VERSION ""

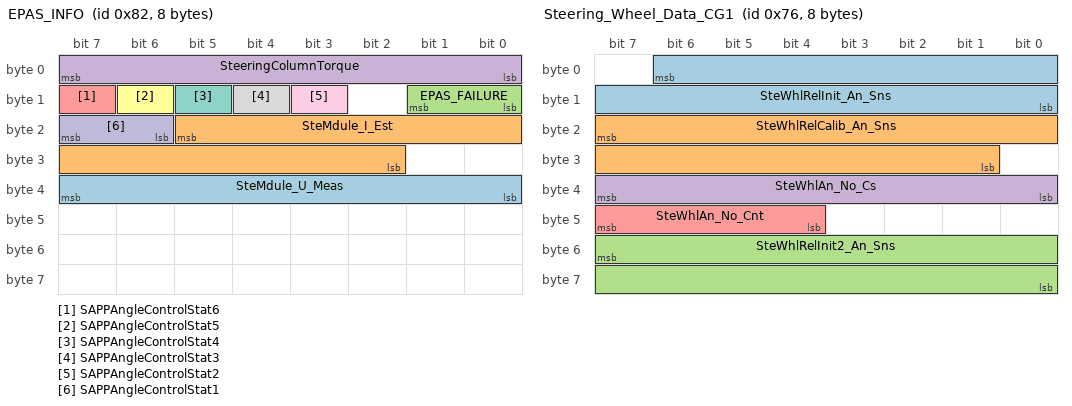
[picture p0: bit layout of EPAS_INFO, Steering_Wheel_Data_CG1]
BO_ 130 EPAS_INFO: 8 XXX
 SG_ SteMdule_U_Meas : 39|8@0+ (0.05,6.0) [0|0] "Volts" XXX
 SG_ SteMdule_I_Est : 21|12@0+ (0.05,-64.0) [0|0] "Amps" XXX
 SG_ EPAS_FAILURE : 9|2@0+ (1,0) [0|0] "" XXX
 SG_ SteeringColumnTorque : 7|8@0+ (0.0625,-8.0) [0|0] "Nm" XXX
 SG_ SAPPAngleControlStat6 : 15|1@0+ (1,0) [0|0] "" XXX
 SG_ SAPPAngleControlStat5 : 14|1@0+ (1,0) [0|0] "" XXX
 SG_ SAPPAngleControlStat4 : 13|1@0+ (1,0) [0|0] "" XXX
 SG_ SAPPAngleControlStat3 : 12|1@0+ (1,0) [0|0] "" XXX
 SG_ SAPPAngleControlStat2 : 11|1@0+ (1,0) [0|0] "" XXX
 SG_ SAPPAngleControlStat1 : 23|2@0+ (1,0) [0|0] "" XXX

BO_ 118 Steering_Wheel_Data_CG1: 8 XXX
 SG_ SteWhlRelInit_An_Sns : 6|15@0+ (0.1,-1600.0) [0|0] "deg" XXX
 SG_ SteWhlRelCalib_An_Sns : 23|15@0+ (0.1,-1600.0) [0|0] "deg" XXX
 SG_ SteWhlRelInit2_An_Sns : 55|16@0+ (0.1,-3200.0) [0|0] "deg" XXX
 SG_ SteWhlAn_No_Cs : 39|8@0+ (1,0) [0|0] "" XXX
 SG_ SteWhlAn_No_Cnt : 47|4@0+ (1,0) [0|0] "Counts" XXX

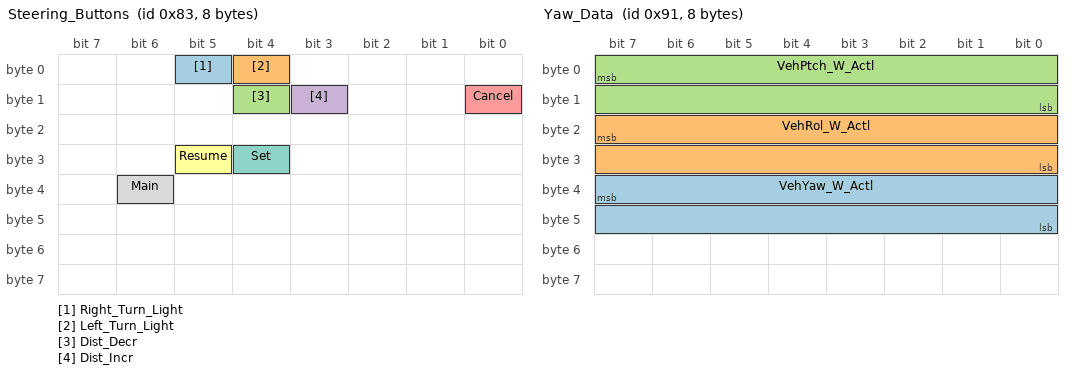
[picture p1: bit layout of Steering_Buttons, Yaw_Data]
BO_ 131 Steering_Buttons: 8 XXX
 SG_ Right_Turn_Light : 5|1@0+ (1,0) [0|0] "" XXX
 SG_ Left_Turn_Light : 4|1@0+ (1,0) [0|0] "" XXX
 SG_ Dist_Decr : 12|1@0+ (1,0) [0|0] "" XXX
 SG_ Dist_Incr : 11|1@0+ (1,0) [0|0] "" XXX
 SG_ Cancel : 8|1@0+ (1,0) [0|0] "" XXX
 SG_ Resume : 29|1@0+ (1,0) [0|0] "" XXX
 SG_ Set : 28|1@0+ (1,0) [0|0] "" XXX
 SG_ Main : 38|1@0+ (1,0) [0|0] "" XXX

BO_ 145 Yaw_Data: 8 XXX
 SG_ VehYaw_W_Actl : 39|16@0+ (0.0002,-6.5) [0|0] "rad/s" XXX
 SG_ VehRol_W_Actl : 23|16@0+ (0.0002,-6.5) [0|0] "rad/s" XXX
 SG_ VehPtch_W_Actl : 7|16@0+ (0.0002,-6.5) [0|0] "rad/s" XXX

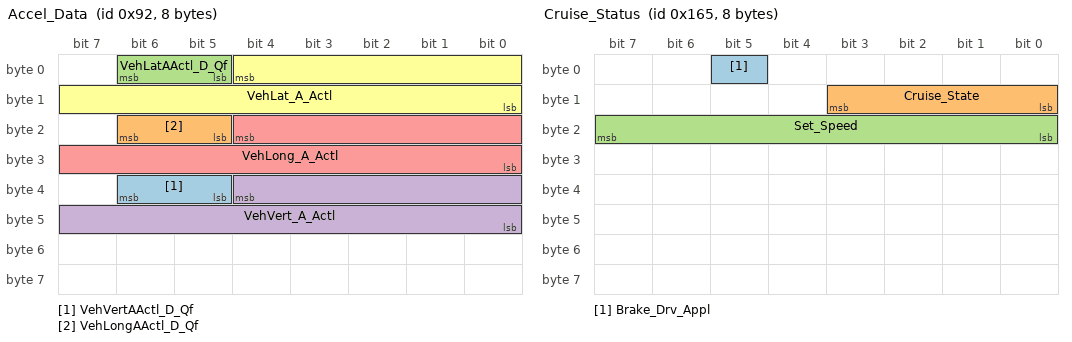
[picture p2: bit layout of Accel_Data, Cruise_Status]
BO_ 146 Accel_Data: 8 XXX
 SG_ VehVertAActl_D_Qf : 38|2@0+ (1,0) [0|0] "" XXX
 SG_ VehLongAActl_D_Qf : 22|2@0+ (1,0) [0|0] "" XXX
 SG_ VehLatAActl_D_Qf : 6|2@0+ (1,0) [0|0] "" XXX
 SG_ VehVert_A_Actl : 36|13@0+ (0.01,-40.0) [0|0] "m/s^2" XXX
 SG_ VehLong_A_Actl : 20|13@0+ (0.01,-40.0) [0|0] "m/s^2" XXX
 SG_ VehLat_A_Actl : 4|13@0+ (0.01,-40.0) [0|0] "m/s^2" XXX

BO_ 357 Cruise_Status: 8 XXX
 SG_ Brake_Drv_Appl : 5|1@0+ (1,0) [0|0] "" XXX
 SG_ Cruise_State : 11|4@0+ (1,0) [0|0] "" XXX
 SG_ Set_Speed : 23|8@0+ (1,0) [0|0] "" XXX

BO_ 516 EngineData_14: 8 XXX
 SG_ ApedPosScal_Pc_Actl : 1|10@0+ (0.1,0) [0|0] "%" XXX

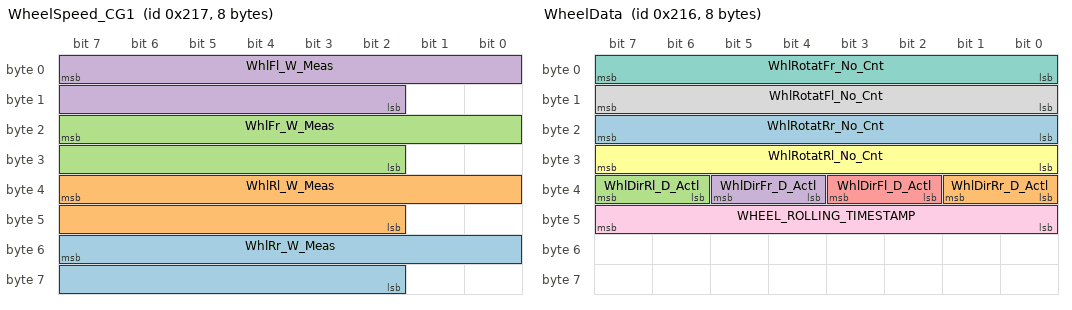
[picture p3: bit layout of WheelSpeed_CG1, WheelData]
BO_ 535 WheelSpeed_CG1: 8 XXX
 SG_ WhlRr_W_Meas : 55|14@0+ (0.04,0) [0|0] "rad/s" XXX
 SG_ WhlRl_W_Meas : 39|14@0+ (0.04,0) [0|0] "rad/s" XXX
 SG_ WhlFr_W_Meas : 23|14@0+ (0.04,0) [0|0] "rad/s" XXX
 SG_ WhlFl_W_Meas : 7|14@0+ (0.04,0) [0|0] "rad/s" XXX

BO_ 534 WheelData: 8 XXX
 SG_ WhlRotatRr_No_Cnt : 23|8@0+ (1,0) [0|0] "" XXX
 SG_ WhlDirRr_D_Actl : 33|2@0+ (1,0) [0|0] "" XXX
 SG_ WhlDirRl_D_Actl : 39|2@0+ (1,0) [0|0] "" XXX
 SG_ WhlDirFr_D_Actl : 37|2@0+ (1,0) [0|0] "" XXX
 SG_ WhlDirFl_D_Actl : 35|2@0+ (1,0) [0|0] "" XXX
 SG_ WhlRotatRl_No_Cnt : 31|8@0+ (1,0) [0|0] "" XXX
 SG_ WhlRotatFr_No_Cnt : 7|8@0+ (1,0) [0|0] "" XXX
 SG_ WhlRotatFl_No_Cnt : 15|8@0+ (1,0) [0|0] "" XXX
 SG_ WHEEL_ROLLING_TIMESTAMP : 47|8@0+ (1,0) [0|0] "" XXX

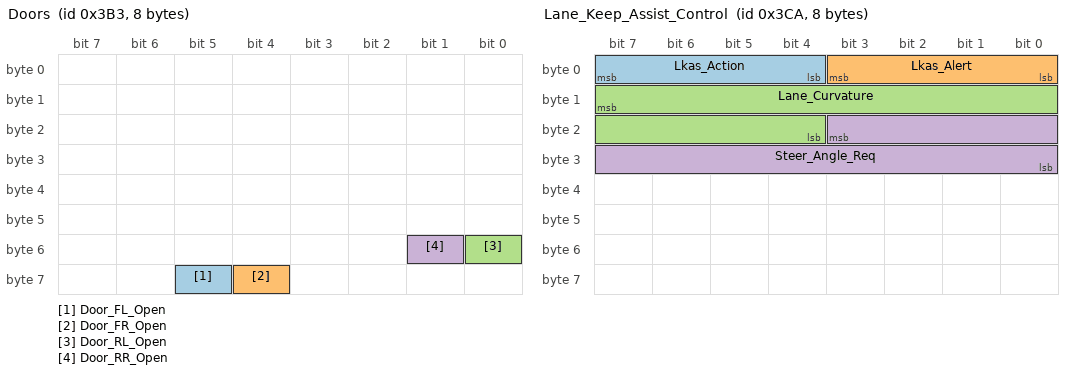
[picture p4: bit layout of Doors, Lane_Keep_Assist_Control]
BO_ 947 Doors: 8 XXX
 SG_ Door_FL_Open : 61|1@0+ (1,0) [0|0] "" XXX
 SG_ Door_FR_Open : 60|1@0+ (1,0) [0|0] "" XXX
 SG_ Door_RL_Open : 48|1@0+ (1,0) [0|0] "" XXX
 SG_ Door_RR_Open : 49|1@0+ (1,0) [0|0] "" XXX

BO_ 963 BCM_to_HS_Body: 8 XXX
 SG_ Brake_Lights : 8|1@0+ (1,0) [0|0] "" XXX

BO_ 970 Lane_Keep_Assist_Control: 8 XXX
 SG_ Lkas_Action : 7|4@0+ (1,0) [0|15] "" XXX
 SG_ Lkas_Alert : 3|4@0+ (1,0) [0|15] "" XXX
 SG_ Lane_Curvature : 15|12@0+ (5e-06,-0.01) [0|0] "1/m" XXX
 SG_ Steer_Angle_Req : 19|12@0+ (0.04297,-88.00445) [0|0] "deg" XXX

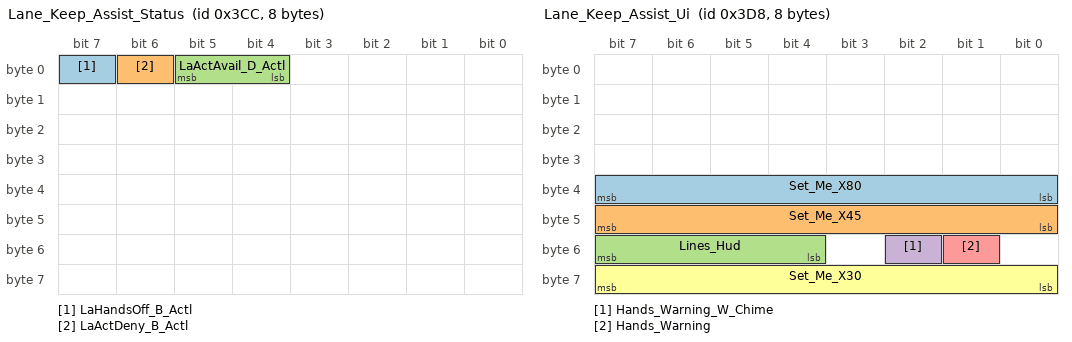
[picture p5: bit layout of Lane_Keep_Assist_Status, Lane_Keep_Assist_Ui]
BO_ 972 Lane_Keep_Assist_Status: 8 XXX
 SG_ LaHandsOff_B_Actl : 7|1@0+ (1,0) [0|0] "" XXX
 SG_ LaActDeny_B_Actl : 6|1@0+ (1,0) [0|0] "" XXX
 SG_ LaActAvail_D_Actl : 5|2@0+ (1,0) [0|0] "" XXX

BO_ 984 Lane_Keep_Assist_Ui: 8 XXX
 SG_ Set_Me_X80 : 39|8@0+ (1,0) [0|255] "" XXX
 SG_ Set_Me_X45 : 47|8@0+ (1,0) [0|255] "" XXX
 SG_ Lines_Hud : 55|4@0+ (1,0) [0|15] "" XXX
 SG_ Hands_Warning_W_Chime : 50|1@0+ (1,0) [0|1] "" XXX
 SG_ Hands_Warning : 49|1@0+ (1,0) [0|1] "" XXX
 SG_ Set_Me_X30 : 63|8@0+ (1,0) [0|255] "" XXX

BU_: ADAS RADAR NEO XXX

CM_ SG_ 970 Lkas_Action "only vals 4, 5, 8, 9 seem to work. 4 and 5 are a bit smoother" ;

VAL_ 513 STATE 5 "FAULT_TIMEOUT" 4 "FAULT_STARTUP" 3 "FAULT_SCE" 2 "FAULT_SEND" 1 "FAULT_BAD_CHECKSUM" 0 "NO_FAULT" ;

VAL_ 780 CRUISE_SPEED 255 "no_speed" 252 "stopped";
VAL_ 780 HUD_LEAD 3 "acc_off" 2 "solid_car" 1 "dashed_car" 0 "no_car";
VAL_ 884 DASHBOARD_ALERT 0 "none" 51 "acc_problem" 55 "cmbs_problem" 75 "key_not_detected" 79 "fasten_seatbelt" 111 "lkas_problem" 131 "brake_system_problem" 132 "brake_hold_problem" 139 "tbd" 161 "door_open";
VAL_ 891 WIPERS 4 "High" 2 "Low" 0 "Off";

VAL_ 506 FCW 3 "fcw" 2 "fcw" 1 "fcw" 0 "no_fcw";
VAL_ 506 CHIME 4 "double_chime" 3 "single_chime" 2 "continuous_chime" 1 "repeating_chime" 0 "no_chime";
VAL_ 506 AEB_STATUS 3 "aeb_prepare" 2 "aeb_ready" 1 "aeb_braking" 0 "no_aeb";
VAL_ 829 BEEP 3 "single_beep" 2 "triple_beep" 1 "repeated_beep" 0 "no_beep";

VAL_ 399 STEER_STATUS 6 "tmp_fault" 5 "fault_1" 4 "no_torque_alert_2" 3 "low_speed_lockout" 2 "no_torque_alert_1" 0 "normal" ;
VAL_ 401 GEAR_SHIFTER 32 "L" 16 "S" 8 "D" 4 "N" 2 "R" 1 "P" ;
VAL_ 401 GEAR 7 "L" 10 "S" 4 "D" 3 "N" 2 "R" 1 "P" ;
VAL_ 422 CRUISE_BUTTONS 7 "tbd" 6 "tbd" 5 "tbd" 4 "accel_res" 3 "decel_set" 2 "cancel" 1 "main" 0 "none" ;
VAL_ 422 LIGHTS_SETTING 3 "high_beam" 2 "low_beam" 1 "position" 0 "no_lights" ;
